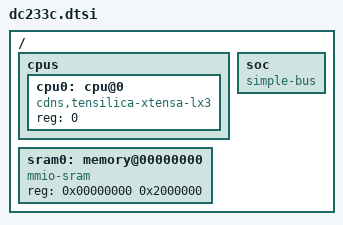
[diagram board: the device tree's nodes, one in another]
/*
 * Copyright (c) 2023 Intel Corporation.
 *
 * SPDX-License-Identifier: Apache-2.0
 */

#include "skeleton.dtsi"

/ {
	cpus {
		#address-cells = <1>;
		#size-cells = <0>;

		cpu0: cpu@0 {
			device_type = "cpu";
			compatible = "cdns,tensilica-xtensa-lx3";
			reg = <0>;
		};
	};

	sram0: memory@00000000 {
		device_type = "memory";
		compatible = "mmio-sram";
		reg = <0x00000000 0x2000000>;
	};

	soc {
		#address-cells = <1>;
		#size-cells = <1>;
		compatible = "simple-bus";
		ranges;

	};
};
